# MK30D7 register map
Vendor: Freescale Semiconductor, Inc.; Series: Kinetis_K; File version: 1.6
CPU: CM4 r0p1, little endian, no MPU, no FPU, VTOR, 4 interrupt priority bits
Registers are 32-bit, read-write, reset 0x0 unless marked. A register's access mark holds for its fields unless they carry their own. Offsets are from the block's base; [hi:lo] are bit positions; {n}, {i} and the like mark numbered series; 'fields as' and 'values as' point back to an identical list.

## DAC0 — 12-Bit Digital-to-Analog Converter
Base 0x400CC000; register names take the prefix DAC0_
{0x0+2i} DAT{i}L (i=0..15) 8-bit — DAC Data Low Register
  [7:0] DATA
{0x1+2i} DAT{i}H (i=0..15) 8-bit — DAC Data High Register
  [3:0] DATA
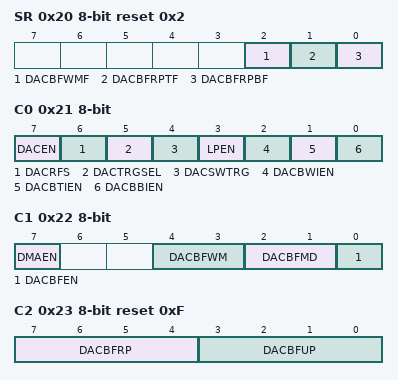
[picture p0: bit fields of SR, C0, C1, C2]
0x20 SR 8-bit reset 0x2 — DAC Status Register
  [2] DACBFWMF — DAC buffer watermark flag
    0=The DAC buffer read pointer has not reached the watermark level; 1=The DAC buffer read pointer has reached the watermark level
  [1] DACBFRPTF — DAC buffer read pointer top position flag
    0=The DAC buffer read pointer is not zero; 1=The DAC buffer read pointer is zero
  [0] DACBFRPBF — DAC buffer read pointer bottom position flag
    0=The DAC buffer read pointer is not equal to the DACBFUP; 1=The DAC buffer read pointer is equal to the DACBFUP
0x21 C0 8-bit — DAC Control Register
  [7] DACEN — DAC enable
    0=The DAC system is disabled; 1=The DAC system is enabled
  [6] DACRFS — DAC Reference Select
    0=The DAC selets DACREF_1 as the reference voltage; 1=The DAC selets DACREF_2 as the reference voltage
  [5] DACTRGSEL — DAC trigger select
    0=The DAC hardware trigger is selected; 1=The DAC software trigger is selected
  [4] DACSWTRG wo — DAC software trigger
    0=The DAC soft trigger is not valid; 1=The DAC soft trigger is valid
  [3] LPEN — DAC low power control
    0=high power mode; 1=low power mode
  [2] DACBWIEN — DAC buffer watermark interrupt enable
    0=The DAC buffer watermark interrupt is disabled; 1=The DAC buffer watermark interrupt is enabled
  [1] DACBTIEN — DAC buffer read pointer top flag interrupt enable
    0=The DAC buffer read pointer top flag interrupt is disabled; 1=The DAC buffer read pointer top flag interrupt is enabled
  [0] DACBBIEN — DAC buffer read pointer bottom flag interrupt enable
    0=The DAC buffer read pointer bottom flag interrupt is disabled; 1=The DAC buffer read pointer bottom flag interrupt is enabled
0x22 C1 8-bit — DAC Control Register 1
  [7] DMAEN — DMA enable select
    0=DMA disabled; 1=DMA enabled. When DMA enabled, DMA request will be generated by original interrupts. And interrupts will not be presented on this module at the same time.
  [4:3] DACBFWM — DAC buffer watermark select
    0=1 word; 1=2 words; 2=3 words; 3=4 words
  [2:1] DACBFMD — DAC buffer work mode select
    0=Normal Mode; 1=Swing Mode; 2=One-Time Scan Mode
  [0] DACBFEN — DAC buffer enable
    0=Buffer read pointer disabled. The converted data is always the first word of the buffer.; 1=Buffer read pointer enabled. The converted data is the word that the read pointer points to. It means converted data can be from any word of the buffer.
0x23 C2 8-bit reset 0xF — DAC Control Register 2
  [7:4] DACBFRP — DAC buffer read pointer
  [3:0] DACBFUP — DAC buffer upper limit

## PTA — General Purpose Input/Output
Base 0x400FF000; register names take the prefix GPIOA_
0x00 PDOR — Port Data Output Register
  [31:0] PDO — Port Data Output
    0=Logic level 0 is driven on pin provided pin is configured for General Purpose Output; 1=Logic level 1 is driven on pin provided pin is configured for General Purpose Output
0x04 PSOR wo — Port Set Output Register
  [31:0] PTSO — Port Set Output
    0=Corresponding bit in PDORn does not change; 1=Corresponding bit in PDORn is set to logic one
0x08 PCOR wo — Port Clear Output Register
  [31:0] PTCO — Port Clear Output
    0=Corresponding bit in PDORn does not change; 1=Corresponding bit in PDORn is cleared to logic zero
0x0C PTOR wo — Port Toggle Output Register
  [31:0] PTTO — Port Toggle Output
    0=Corresponding bit in PDORn does not change; 1=Corresponding bit in PDORn is set to the inverse of its existing logic state
0x10 PDIR ro — Port Data Input Register
  [31:0] PDI — Port Data Input
    0=Pin logic level is logic zero or is configured for use by digital function; 1=Pin logic level is logic one
0x14 PDDR — Port Data Direction Register
  [31:0] PDD — Port data direction
    0=Pin is configured as general purpose input, if configured for the GPIO function; 1=Pin is configured for general purpose output, if configured for the GPIO function

## PTB — General Purpose Input/Output
Base 0x400FF040; register names take the prefix GPIOB_
Registers as PTA.

## PTC — General Purpose Input/Output
Base 0x400FF080; register names take the prefix GPIOC_
Registers as PTA; these are added or differ:
0x08 PCOR wo — Port Clear Output Register
  [31:0] PTCO — Port Clear Output
    0=Corresponding bit in PDORn does not change; 1=Corresponding bit in PDORn is cleared to logic zero

## PTD — General Purpose Input/Output
Base 0x400FF0C0; register names take the prefix GPIOD_
Registers as PTA.

## PTE — General Purpose Input/Output
Base 0x400FF100; register names take the prefix GPIOE_
Registers as PTA.

## SysTick — System timer
Base 0xE000E010; register names take the prefix SYST_
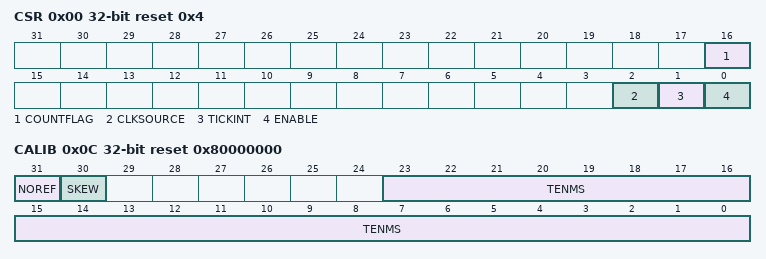
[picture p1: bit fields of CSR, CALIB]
0x00 CSR reset 0x4 — SysTick Control and Status Register
  [16] COUNTFLAG
  [2] CLKSOURCE
    0=external clock; 1=processor clock
  [1] TICKINT
    0=counting down to 0 does not assert the SysTick exception request; 1=counting down to 0 asserts the SysTick exception request
  [0] ENABLE
    0=counter disabled; 1=counter enabled
0x04 RVR — SysTick Reload Value Register
  [23:0] RELOAD — Value to load into the SysTick Current Value Register when the counter reaches 0
0x08 CVR — SysTick Current Value Register
  [23:0] CURRENT — Current value at the time the register is accessed
0x0C CALIB ro reset 0x80000000 — SysTick Calibration Value Register
  [31] NOREF
    0=The reference clock is provided; 1=The reference clock is not provided
  [30] SKEW
    0=10ms calibration value is exact; 1=10ms calibration value is inexact, because of the clock frequency
  [23:0] TENMS — Reload value to use for 10ms timing

## NVIC — Nested Vectored Interrupt Controller
Base 0xE000E100
{0x0+4i} NVICISER{i} (i=0..3) — Interrupt Set Enable Register n
  [31:0] SETENA — Interrupt set enable bits
{0x80+4i} NVICICER{i} (i=0..3) — Interrupt Clear Enable Register n
  [31:0] CLRENA — Interrupt clear-enable bits
{0x100+4i} NVICISPR{i} (i=0..3) — Interrupt Set Pending Register n
  [31:0] SETPEND — Interrupt set-pending bits
{0x180+4i} NVICICPR{i} (i=0..3) — Interrupt Clear Pending Register n
  [31:0] CLRPEND — Interrupt clear-pending bits
{0x200+4i} NVICIABR{i} (i=0..3) — Interrupt Active bit Register n
  [31:0] ACTIVE — Interrupt active flags
{0x300+i} NVICIP{i} 8-bit (i=0..105) — Interrupt Priority Register n
  [7:0] PRI{i} — Priority of interrupt {i}
0xE00 NVICSTIR — Software Trigger Interrupt Register
  [8:0] INTID — Interrupt ID of the interrupt to trigger, in the range 0-239. For example, a value of 0x03 specifies interrupt IRQ3.

## MCM — Core Platform Miscellaneous Control Module
Base 0xE0080000; register names take the prefix MCM_
0x08 PLASC 16-bit ro reset 0x1F — Crossbar switch (AXBS) slave configuration
  [7:0] ASC — Each bit in the ASC field indicates if there is a corresponding connection to the crossbar switch's slave input port.
    0=A bus slave connection to AXBS input port n is absent; 1=A bus slave connection to AXBS input port n is present
0x0A PLAMC 16-bit ro reset 0x3F — Crossbar switch (AXBS) master configuration
  [7:0] AMC — Each bit in the AMC field indicates if there is a corresponding connection to the AXBS master input port.
    0=A bus master connection to AXBS input port n is absent; 1=A bus master connection to AXBS input port n is present
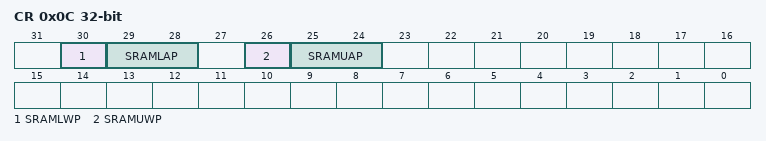
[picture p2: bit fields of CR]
0x0C CR — Control register
  [30] SRAMLWP — SRAM_L write protect
  [29:28] SRAMLAP — SRAM_L arbitration priority
    0=Round robin; 1=Special round robin (favors SRAM backoor accesses over the processor); 2=Fixed priority. Processor has highest, backdoor has lowest; 3=Fixed priority. Backdoor has highest, processor has lowest
  [26] SRAMUWP — SRAM_U write protect
  [25:24] SRAMUAP — SRAM_U arbitration priority
    values as SRAMLAP
